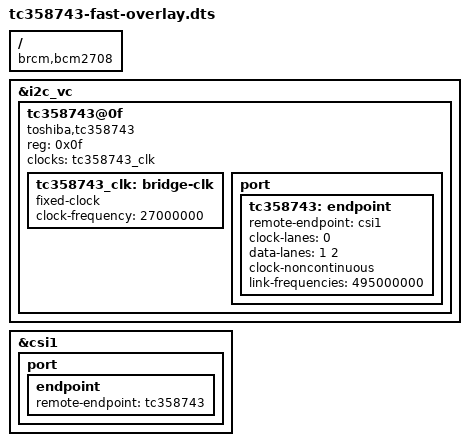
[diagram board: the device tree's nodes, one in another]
// Definitions for Toshiba TC358743 HDMI to CSI2 bridge on VC I2C bus
/dts-v1/;
/plugin/;

/{
	compatible = "brcm,bcm2708";

	fragment@0 {
		target = <&i2c_vc>;
		__overlay__ {
			#address-cells = <1>;
			#size-cells = <0>;
			status = "okay";

			tc358743@0f {
				compatible = "toshiba,tc358743";
				reg = <0x0f>;
				status = "okay";

				clocks = <&tc358743_clk>;
				clock-names = "refclk";

				tc358743_clk: bridge-clk {
					compatible = "fixed-clock";
					#clock-cells = <0>;
					clock-frequency = <27000000>;
				};

				port {
					tc358743: endpoint {
						remote-endpoint = <&csi1>;
						clock-lanes = <0>;
						data-lanes = <1 2>;
						clock-noncontinuous;
						link-frequencies =
							/bits/ 64 <495000000>;
					};
				};
			};
		};
	};

	fragment@1 {
		target = <&csi1>;
		__overlay__ {
			#address-cells = <1>;
			#size-cells = <0>;
			status = "okay";

			port {
				#address-cells = <1>;
				#size-cells = <0>;
				endpoint {
					remote-endpoint = <&tc358743>;
				};
			};
		};
	};
};
